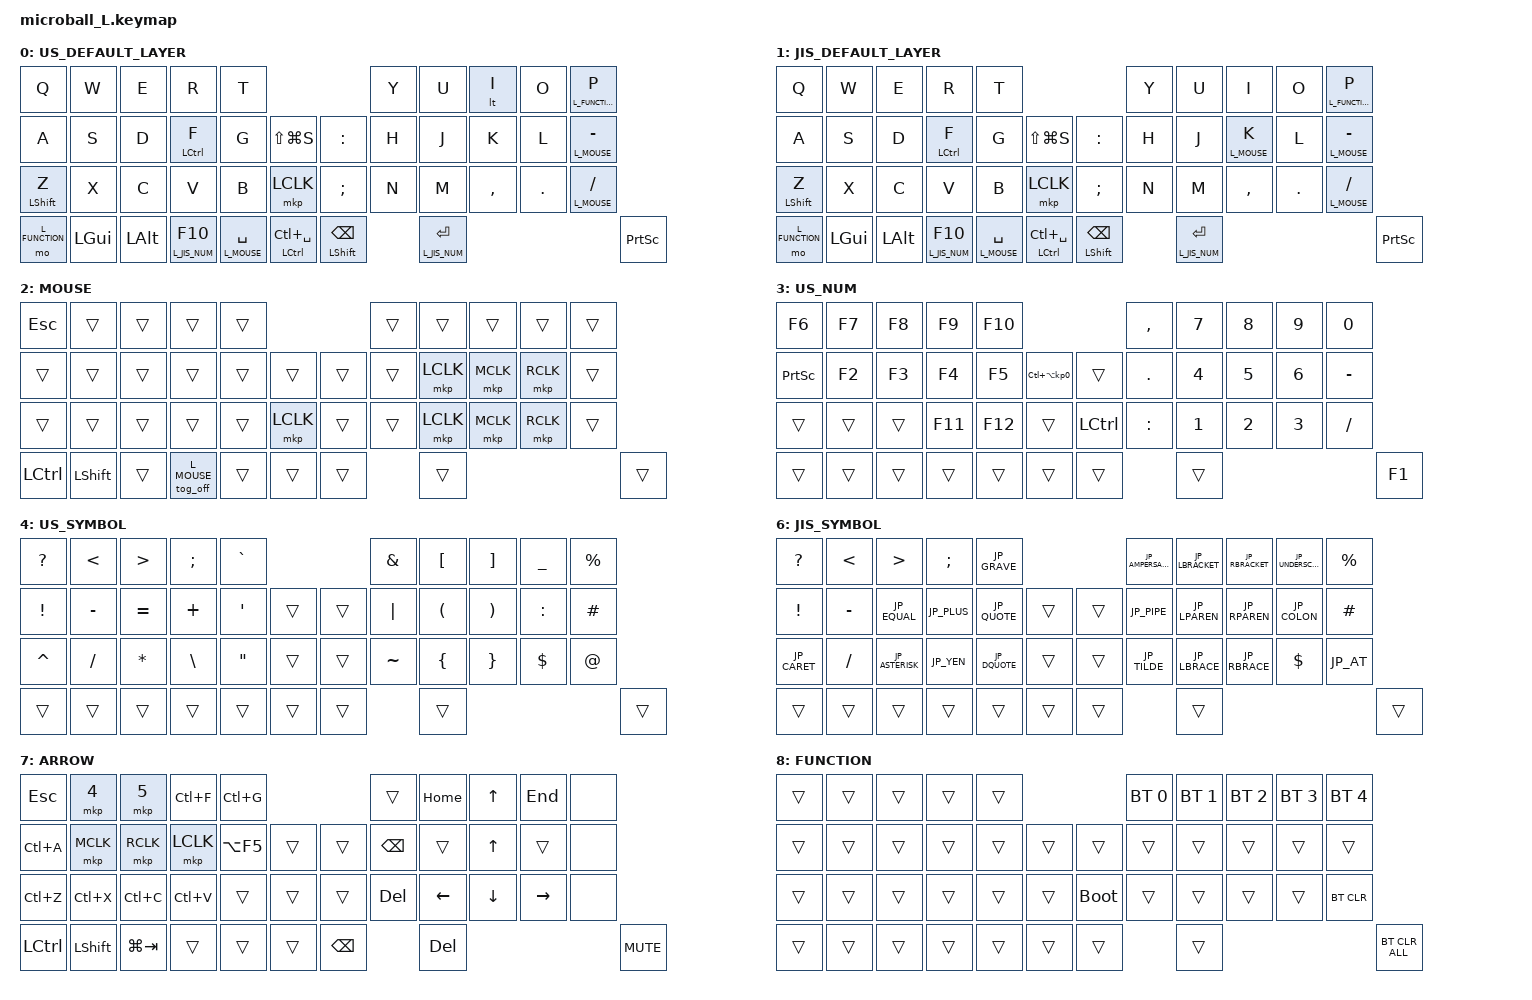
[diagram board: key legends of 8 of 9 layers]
#include <behaviors.dtsi>
#include <input/processors.dtsi>
#include <dt-bindings/zmk/bt.h>
#include <dt-bindings/zmk/keys.h>
#include <dt-bindings/zmk/pointing.h>

// #includeのあとのあたりにスクロール量変更の定義を追記
#define ZMK_POINTING_DEFAULT_SCRL_VAL 80

#define LEFT_HAND_KEYS   \
     0  1  2  3  4       \
    10 11 12 13 14 15    \
    22 23 24 25 26 27    \
    34 35 36

#define RIGHT_HAND_KEYS  \
                             5  6  7  8  9 \
                         16 17 18 19 20 21 \
                         28 29 30 31 32 33 \
                                        42

#define LEFT_THUMB_KEYS  \
             37 38 39 

#define RIGHT_THUMB_KEYS \
                         40 41

#define L_US_DEFAULT 0
#define L_JIS_DEFAULT 1
#define L_MOUSE 2
#define L_US_NUM 3
#define L_US_SYMBOL 4
#define L_JIS_NUM 5
#define L_JIS_SYMBOL 6
#define L_ARROW 7
#define L_FUNCTION 8

// OS設定を日本語キーボードのまま使用するための変換定義
#define JP_DQUOTE       AT                // "
#define JP_AMPERSAND    CARET             // &
#define JP_QUOTE        AMPERSAND         // '
#define JP_EQUAL        UNDER             // =
#define JP_CARET        EQUAL             // ^
#define JP_YEN          0x89              // ¥
#define JP_PLUS         COLON             // +
#define JP_TILDE        PLUS              // ~
#define JP_PIPE         LS(0x89)          // |
#define JP_AT           LEFT_BRACKET      // @
#define JP_COLON        SINGLE_QUOTE      // :
#define JP_ASTERISK     DOUBLE_QUOTES     // *
#define JP_UNDERSCORE   LS(0x87)          // _
#define JP_GRAVE        LS(LEFT_BRACE)    // `
#define JP_LBRACKET     RIGHT_BRACKET     // [
#define JP_RBRACKET     BACKSLASH         // ]
#define JP_LPAREN       ASTERISK          // (
#define JP_RPAREN       LEFT_PARENTHESIS  // )
#define JP_LBRACE       RIGHT_BRACE       // {
#define JP_RBRACE       PIPE              // }
#define JP_KANA         LANGUAGE_1        // かな
#define JP_EISU         LANGUAGE_2        // 英数
#define JP_HANZEN       GRAVE             // 半角/全角

&mt {
    flavor = "balanced";
    tapping-term-ms = <165>;
    quick-tap-ms = <0>;
};

&lt {
    flavor = "balanced";
    tapping-term-ms = <165>;
    quick-tap-ms = <0>;
};

/*
&sl {
    release-after-ms = <250>;  // ダブルクリックに必要な時間を設定
};
*/

&mkp_input_listener {
    input-processors = <&zip_temp_layer L_MOUSE 10000>;
};

/ {
    combos {
        compatible = "zmk,combos";

        tab {
            bindings = <&kp TAB>;
            key-positions = <11 12>;
        };

        shift_tab {
            bindings = <&kp LS(TAB)>;
            key-positions = <12 13>;
        };

        esc {
            bindings = <&kp ESC>;
            key-positions = <0 1>;
        };

        double_quotation {
            bindings = <&kp DOUBLE_QUOTES>;
            key-positions = <20 21>;
        };

        eq {
            bindings = <&kp EQUAL>;
            key-positions = <24 25>;
        };

        alt_tab {
            bindings = <&app_switch>;
            key-positions = <11 36>;
        };

        win_tab {
            bindings = <&task_switch>;
            key-positions = <10 36>;
        };
    };

    macros {
        to_layer_0: to_layer_0 {
            compatible = "zmk,behavior-macro-one-param";
            #binding-cells = <1>;
            bindings = <&to 0 &macro_param_1to1 &kp MACRO_PLACEHOLDER>;
            label = "TO_LAYER_0";
        };

        lt_aml_off_and_mo: lt_aml_off_and_mo {
            compatible = "zmk,behavior-macro-one-param";
            #binding-cells = <1>;
            bindings
                = <&macro_tap>
                , <&tog_off L_MOUSE>
                , <&macro_param_1to1>
                , <&macro_press &mo MACRO_PLACEHOLDER>
                , <&macro_pause_for_release>
                , <&macro_param_1to1>
                , <&macro_release &mo MACRO_PLACEHOLDER>            
                ;
            label = "LT_AML_OFF_AND_MO";
        };

        /*
        mkp_exit_AML: mkp_exit_AML {
            compatible = "zmk,behavior-macro-one-param";
            #binding-cells = <1>;
            bindings
                = <&macro_press>
                , <&macro_param_1to1 &mkp MACRO_PLACEHOLDER>
                , <&macro_pause_for_release>
                , <&macro_release>
                , <&macro_param_1to1 &mkp MACRO_PLACEHOLDER>
                , <&macro_tap>
                , <&sl L_MOUSE>
                ;
            label = "MKP_EXIT_AML";
        };
        */

        to_us_default_layer: to_us_default_layer {
            compatible = "zmk,behavior-macro";
            #binding-cells = <0>;
            bindings
                = <&macro_tap>
                , <&tog_off L_JIS_DEFAULT>
                , <&tog_off L_JIS_NUM>
                , <&tog_off L_JIS_SYMBOL>
                , <&tog_on L_US_NUM>
                , <&tog_on L_US_SYMBOL>
                , <&to L_US_DEFAULT>
                ;
            label = "TO_US_DEFAULT_LAYER";
        };

        to_jis_default_layer: to_jis_default_layer {
            compatible = "zmk,behavior-macro";
            #binding-cells = <0>;
            bindings
                = <&macro_tap>
                , <&tog_off L_US_NUM>
                , <&tog_off L_US_SYMBOL>
                , <&tog_on L_JIS_DEFAULT>
                , <&tog_on L_JIS_NUM>
                , <&tog_on L_JIS_SYMBOL>
                , <&to L_JIS_DEFAULT>
                ;
            label = "TO_JIS_DEFAULT_LAYER";
        };

        app_switch: app_switch {
            compatible = "zmk,behavior-macro";
            #binding-cells = <0>;
            wait-ms = <40>;
            tap-ms = <100>;
            bindings
                = <&macro_press   &kp LALT>
                , <&macro_tap     &kp TAB>
                , <&macro_tap     &sk LALT>
                , <&macro_release &kp LALT>
                ;
            label = "APP_SWITCH";
        };

        task_switch: task_switch {
            compatible = "zmk,behavior-macro";
            #binding-cells = <0>;
            wait-ms = <40>;
            tap-ms = <100>;
            bindings
                = <&macro_press   &kp LGUI>
                , <&macro_tap     &kp TAB>
                , <&macro_tap     &sk LGUI>
                , <&macro_release &kp LGUI>
                ;
            label = "TASK_SWITCH";
        };
    };

    behaviors {
        lt_to_layer_0: lt_to_layer_0 {
            compatible = "zmk,behavior-hold-tap";
            display-name = "LAYER_TAP_TO_0";
            bindings = <&mo>, <&to_layer_0>;

            #binding-cells = <2>;
            tapping-term-ms = <165>;
        };

        lt_aml_off: lt_aml_off {
            compatible = "zmk,behavior-hold-tap";
            display-name = "LT_AML_OFF";
            bindings = <&lt_aml_off_and_mo>, <&kp>;

            #binding-cells = <2>;
            tapping-term-ms = <165>;
        };

        bsands: backspace_and_shift {
            compatible = "zmk,behavior-hold-tap";
            label = "BS_AND_SHIFT";
            #binding-cells = <2>;
            flavor = "tap-unless-interrupted";
            tapping-term-ms = <200>;
            quick-tap-ms = <125>;
            global-quick-tap;
            bindings = <&kp>, <&kp>;
        };

        bspc_del: backspace_delete {
            compatible = "zmk,behavior-mod-morph";
            #binding-cells = <0>;
            bindings = <&kp BACKSPACE>, <&kp DELETE>;
            mods = <(MOD_LSFT|MOD_RSFT)>;
            keep-mods = <(MOD_RSFT)>;
        };

        tog_on: toggle_layer_on_only {
            compatible = "zmk,behavior-toggle-layer";
            #binding-cells = <1>;
            display-name = "Toggle Layer On";
            toggle-mode = "on";
        };

        tog_off: toggle_layer_off_only {
            compatible = "zmk,behavior-toggle-layer";
            #binding-cells = <1>;
            display-name = "Toggle Layer Off";
            toggle-mode = "off";
        };

        hml: home_row_mod_left {
            compatible = "zmk,behavior-hold-tap";
            #binding-cells = <2>;
            flavor = "balanced";
            require-prior-idle-ms = <150>;
            tapping-term-ms = <280>;
            quick-tap-ms = <175>;
            bindings = <&kp>, <&kp>;
            hold-trigger-key-positions = <RIGHT_HAND_KEYS RIGHT_THUMB_KEYS>; // List of keys on the right side of the keyboard
            hold-trigger-on-release;
        };

        hmr: home_row_mod_right {
            compatible = "zmk,behavior-hold-tap";
            #binding-cells = <2>;
            flavor = "balanced";
            require-prior-idle-ms = <150>;
            tapping-term-ms = <280>;
            quick-tap-ms = <175>;
            bindings = <&kp>, <&kp>;
            hold-trigger-key-positions = <LEFT_HAND_KEYS LEFT_THUMB_KEYS>; // List of keys on the left side of the keyboard
            hold-trigger-on-release;
        };

        minus_jis: minus_jis {
            compatible = "zmk,behavior-mod-morph";
            #binding-cells = <0>;
            bindings = <&kp MINUS>, <&kp JP_UNDERSCORE>;
            display-name = "MINUS_JIS";
            mods = <(MOD_LSFT|MOD_RSFT)>;
        };

        // combosやmacrosと同じ階層に以下のbehaviorsを追記
        // スクロール方向を逆にしたい場合は <&msc SCRL_DOWN> と <&msc SCRL_UP> を入れ替えてください
        mouse_wheel_scrl: mouse_wheel_scrl {
            compatible = "zmk,behavior-sensor-rotate-var";
            #sensor-binding-cells = <2>;
            bindings = <&msc>, <&msc>;
            tap-ms = <20>;
        };

      // カスタムバックスペースbehavior
    sands: space_and_shift {
    compatible = "zmk,behavior-hold-tap";
    label = "SPACE_AND_SHIFT";
    #binding-cells = <2>;
    flavor = "tap-unless-interrupted";
    tapping-term-ms = <200>;
    quick-tap-ms = <125>;
    global-quick-tap;
    bindings = <&kp>, <&kp>;
    };

    };

    keymap {
        compatible = "zmk,keymap";

        US_DEFAULT_LAYER {
            bindings = <
&kp Q            &kp W            &kp E              &kp R                      &kp T                                                                                   &kp Y                 &kp U                &lt I                 &kp O            &lt L_FUNCTION P
&kp A            &kp S            &kp D              &mt LEFT_CONTROL F         &kp G                            &kp LS(LG(S))               &kp COLON                  &kp H                 &kp J                &kp K                 &kp L            &lt L_MOUSE MINUS
&mt LEFT_SHIFT Z &kp X            &kp C              &kp V                      &kp B                            &mkp LCLK                   &kp SEMICOLON              &kp N                 &kp M                &kp COMMA             &kp DOT          &lt L_MOUSE SLASH
&mo L_FUNCTION   &kp LEFT_GUI     &kp LEFT_ALT       &lt L_JIS_NUM F10          &lt L_MOUSE SPACE                &mt LEFT_CONTROL LC(SPACE)            &sands LEFT_SHIFT BACKSPACE   &lt L_JIS_NUM ENTER                                                                       &kp PRINTSCREEN
            >;

            sensor-bindings = <&mouse_wheel_scrl SCRL_UP SCRL_DOWN>;
        };

        JIS_DEFAULT_LAYER {
            bindings = <
&kp Q            &kp W            &kp E              &kp R                      &kp T                                                                                   &kp Y                 &kp U                &kp I                 &kp O            &lt L_FUNCTION P
&kp A            &kp S            &kp D              &mt LEFT_CONTROL F         &kp G                            &kp LS(LG(S))               &kp COLON                  &kp H                 &kp J                &lt L_MOUSE K               &kp L            &lt L_MOUSE MINUS
&mt LEFT_SHIFT Z &kp X            &kp C              &kp V                      &kp B                            &mkp LCLK                   &kp SEMICOLON              &kp N                 &kp M                &kp COMMA             &kp DOT          &lt L_MOUSE SLASH
&mo L_FUNCTION   &kp LEFT_GUI     &kp LEFT_ALT       &lt L_JIS_NUM F10                  &lt L_MOUSE SPACE                      &mt LEFT_CONTROL LC(SPACE)            &sands LEFT_SHIFT BACKSPACE   &lt L_JIS_NUM ENTER                                                                       &kp PRINTSCREEN
            >;

            sensor-bindings = <&mouse_wheel_scrl SCRL_UP SCRL_DOWN>;
        };

        MOUSE {
            bindings = <
&kp ESC            &trans           &trans   &trans             &trans                        &trans   &trans      &trans      &trans      &trans
&trans             &trans           &trans   &trans             &trans   &trans      &trans   &trans   &mkp LCLK   &mkp MCLK   &mkp RCLK   &trans
&trans             &trans           &trans   &trans             &trans   &mkp LCLK   &trans   &trans   &mkp LCLK   &mkp MCLK   &mkp RCLK   &trans   
&kp LEFT_CONTROL   &kp LEFT_SHIFT   &trans   &tog_off L_MOUSE   &trans   &trans      &trans   &trans                                       &trans
            >;

            sensor-bindings = <&mouse_wheel_scrl SCRL_UP SCRL_DOWN>;
        };

        US_NUM {
            bindings = <
&kp F6            &kp F7   &kp F8   &kp F9    &kp F10                                                   &kp COMMA      &kp NUMBER_7   &kp NUMBER_8   &kp NUMBER_9   &kp NUMBER_0
&kp PRINTSCREEN   &kp F2   &kp F3   &kp F4    &kp F5    &kp LC(LA(KP_NUMBER_0))      &trans             &kp DOT        &kp NUMBER_4   &kp NUMBER_5   &kp NUMBER_6   &kp MINUS
&trans            &trans   &trans   &kp F11   &kp F12   &trans                       &kp LEFT_CONTROL   &kp COLON      &kp NUMBER_1   &kp NUMBER_2   &kp NUMBER_3   &kp SLASH
&trans            &trans   &trans   &trans    &trans    &trans                       &trans             &trans                                                      &kp F1
            >;
        };

        US_SYMBOL {
            bindings = <
&kp QUESTION     &kp LESS_THAN   &kp GREATER_THAN  &kp SEMICOLON  &kp GRAVE                              &kp AMPERSAND  &kp LEFT_BRACKET      &kp RIGHT_BRACKET      &kp UNDERSCORE  &kp PERCENT
&kp EXCLAMATION  &kp MINUS       &kp EQUAL         &kp PLUS       &kp SINGLE_QUOTE   &trans      &trans  &kp PIPE       &kp LEFT_PARENTHESIS  &kp RIGHT_PARENTHESIS  &kp COLON       &kp HASH
&kp CARET        &kp SLASH       &kp ASTERISK      &kp BACKSLASH  &kp DOUBLE_QUOTES  &trans      &trans  &kp TILDE      &kp LEFT_BRACE        &kp RIGHT_BRACE        &kp DOLLAR      &kp AT_SIGN
&trans           &trans          &trans            &trans         &trans             &trans      &trans  &trans                                                                      &trans
            >;
        };

        JIS_NUM {
            bindings = <
&kp F1                      &kp F2           &kp F3           &kp F4           &kp F5                                                       &kp F6        &kp F7             &kp F8          &kp F9           &kp F10
&kp NUMBER_1      &kp NUMBER_2     &kp NUMBER_3     &kp NUMBER_4     &kp NUMBER_5    &kp LC(LA(KP_NUMBER_0))      &kp UNDERSCORE  &kp NUMBER_6  &kp NUMBER_7       &kp NUMBER_8    &kp NUMBER_9     &kp NUMBER_0
&kp LC(Z)      &kp LC(X)     &kp LC(C)     &kp LC(V)     &kp NUMBER_5    &kp LC(LA(KP_NUMBER_0))      &kp UNDERSCORE  &kp SLASH  &kp CARET       &kp kp TILDE     &kp AT_SIGN     &kp UNDERSCORE
&trans            &trans   &trans   &trans    &trans    &trans                       &trans             &trans                                                      &kp F1
            >;
        };

        JIS_SYMBOL {
            bindings = <
&kp QUESTION     &kp LESS_THAN   &kp GREATER_THAN  &kp SEMICOLON  &kp JP_GRAVE                        &kp JP_AMPERSAND  &kp JP_LBRACKET  &kp JP_RBRACKET  &kp JP_UNDERSCORE  &kp PERCENT
&kp EXCLAMATION  &kp MINUS       &kp JP_EQUAL      &kp JP_PLUS    &kp JP_QUOTE    &trans      &trans  &kp JP_PIPE       &kp JP_LPAREN    &kp JP_RPAREN    &kp JP_COLON       &kp HASH
&kp JP_CARET     &kp SLASH       &kp JP_ASTERISK   &kp JP_YEN     &kp JP_DQUOTE   &trans      &trans  &kp JP_TILDE      &kp JP_LBRACE    &kp JP_RBRACE    &kp DOLLAR         &kp JP_AT
&trans           &trans          &trans            &trans         &trans          &trans      &trans  &trans                                                                 &trans
            >;
        };

        ARROW {
            bindings = <
&kp ESC           &mkp 4       &mkp 5       &kp LC(F)   &kp LC(G)                               &trans         &kp HOME         &kp UP_ARROW     &kp END           &none
&kp LC(A)         &mkp MCLK    &mkp RCLK    &mkp LCLK   &kp LA(F5)  &trans      &trans       &kp BACKSPACE  &trans           &kp UP_ARROW     &trans   &none
&kp LC(Z)         &kp LC(X)    &kp LC(C)    &kp LC(V)   &trans      &trans      &trans       &kp DEL        &kp LEFT_ARROW   &kp DOWN_ARROW   &kp RIGHT_ARROW   &none
&kp LEFT_CONTROL  &kp LEFT_SHIFT  &kp LG(TAB)  &trans   &trans      &trans      &kp BACKSPACE  &kp DEL                                                             &kp K_MUTE
            >;

            sensor-bindings = <&inc_dec_kp LC(PAGE_UP) LC(PAGE_DOWN)>;
        };

        FUNCTION {
            bindings = <
&trans  &trans        &trans        &trans        &trans                           &bt BT_SEL 0  &bt BT_SEL 1  &bt BT_SEL 2  &bt BT_SEL 3  &bt BT_SEL 4
&trans  &trans        &trans        &trans        &trans  &trans      &trans       &trans        &trans        &trans        &trans        &trans
&trans  &trans        &trans        &trans        &trans  &trans      &bootloader  &trans        &trans        &trans        &trans        &bt BT_CLR
&trans  &trans        &trans        &trans        &trans  &trans      &trans       &trans                                                  &bt BT_CLR_ALL
            >;
        };
    };
};
